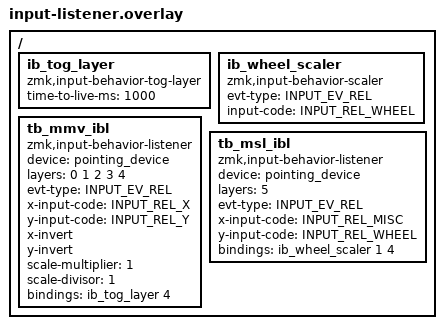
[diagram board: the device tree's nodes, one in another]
#include <dt-bindings/zmk/input_transform.h>

/ {
    ib_tog_layer: ib_tog_layer {
        compatible = "zmk,input-behavior-tog-layer";
        #binding-cells = <1>;
        time-to-live-ms = <1000>;
    };

    ib_wheel_scaler: ib_wheel_scaler {
        compatible = "zmk,input-behavior-scaler";
        #binding-cells = <2>;
        evt-type = <INPUT_EV_REL>;
        input-code = <INPUT_REL_WHEEL>;
    };

    tb_mmv_ibl {
        compatible = "zmk,input-behavior-listener";
        device = <&pointing_device>;
        layers = <0 1 2 3 4>;
        evt-type = <INPUT_EV_REL>;
        x-input-code = <INPUT_REL_X>;
        y-input-code = <INPUT_REL_Y>;
        x-invert;
        y-invert;
        scale-multiplier = <1>;
        scale-divisor = <1>;
        bindings = <&ib_tog_layer 4>;
    };

    tb_msl_ibl {
        compatible = "zmk,input-behavior-listener";
        device = <&pointing_device>;
        layers = <5>;
        evt-type = <INPUT_EV_REL>;
        x-input-code = <INPUT_REL_MISC>;
        y-input-code = <INPUT_REL_WHEEL>;
        /* y-invert を削除してスクロール方向を反転 */
        bindings = <&ib_wheel_scaler 1 4>;
    };
};
